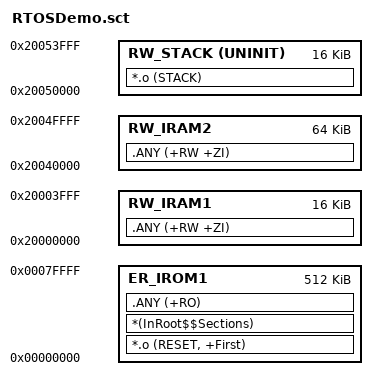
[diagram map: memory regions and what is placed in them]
; *************************************************************
; *** Scatter-Loading Description File generated by uVision ***
; *************************************************************

LR_IROM1 0x00000000 0x00080000  {    ; load region size_region
  ER_IROM1 0x00000000 0x00080000  {  ; load address = execution address
   *.o (RESET, +First)
   *(InRoot$$Sections)
   .ANY (+RO)
  }
  
  RW_IRAM1 0x20000000 0x00004000  {  ; RW data
   .ANY (+RW +ZI)
  }

  RW_IRAM2 0x20040000 0x00010000  {  ; RW data
   .ANY (+RW +ZI)
  }
  
  RW_STACK 0x20050000 UNINIT 0x00004000 {
   *.o (STACK)
  }
}

